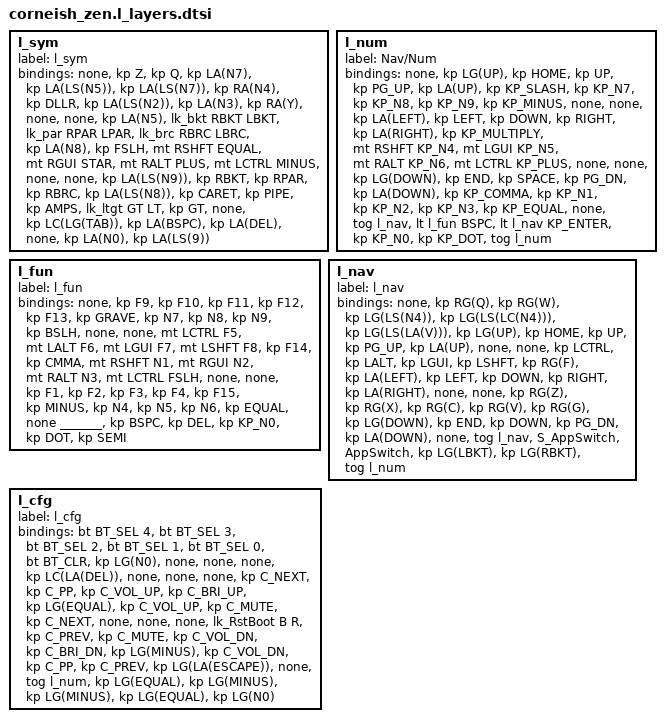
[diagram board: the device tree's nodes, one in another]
/*
 Building for a 36 key on a 42 key board (outside column is unused)
 */

//                                       Symbol & math (for Mac)
//  * left paired symbols are "linger keys" via hold taps. Tap for left, hold for pair with insertion point between
//╭────────────────────────────────────────────╮ ╭──────────────────────────────────────────╮
//|    Z   |    Q    |   ¶   |   †   |    ‡    | |   ¢   |    $   |    €   |    £   |   ¥   |
//|    §   |    [    |   (   |   {   |    •    | |   /   |    =   |    *   |    +   |   -   |
//|    ·   |    ]    |   )   |   }   |    °    | |   ^   |    |   |    &   |    <   |   >   |
//╰──────────────────╮       | dwdlt |  dwdr   | | &none |    ¡   |        ╭────────────────╯
//                   ╰─────────────────────────╯ ╰─────────────────────────╯
                l_sym {
                    label = "l_sym";
                    bindings = <
&none &kp Z &kp Q &kp LA(N7) &kp LA(LS(N5)) &kp LA(LS(N7))                         &kp RA(N4) &kp DLLR  &kp LA(LS(N2)) &kp LA(N3) &kp RA(Y)  &none
&none &kp LA(N5)  &lk_bkt RBKT LBKT &lk_par RPAR LPAR &lk_brc RBRC LBRC &kp LA(N8) &kp FSLH   &mt RSHFT EQUAL &mt RGUI STAR   &mt RALT PLUS  &mt LCTRL MINUS &none
&none &kp LA(LS(N9)) &kp RBKT &kp RPAR &kp RBRC &kp LA(LS(N8))                     &kp CARET  &kp PIPE  &kp AMPS     &lk_ltgt GT LT  &kp GT  &none
                &kp LC(LG(TAB)) &kp LA(BSPC)   &kp LA(DEL)              &none      &kp LA(N0) &kp LA(LS(9))
                    >;
                };

//                                        Nav & NumPad (standard)
//╭─────────────────────────────────────────────╮ ╭────────────────────────────────────────╮
//|   Top  |  HOME  |   UP   |  PG_UP |   ¶up   | |    /   |   7   |   8   |   9   |   -   |
//|  Lword |  LEFT  |  DOWN  |   RGT  |  Rword  | |    *   |  S/4  |  G/5  |  A/6  |  C/+  |
//|   Bot  |   END  |   SPC  |  PG_DN |   ¶dn   | |    ,   |   1   |   2   |   3   |   =   |
//╰─────────────────╮   tog  |  BSPC  |KP_ENTER | |    0   |   .   |  tog  ╭───────────────╯
//                  ╰───────────────────────────╯ ╰────────────────────────╯
                l_num {
                    label = "Nav/Num";
                    bindings = <

&none &kp LG(UP)    &kp HOME  &kp UP    &kp PG_UP  &kp LA(UP)    &kp KP_SLASH    &kp KP_N7 &kp KP_N8 &kp KP_N9 &kp KP_MINUS &none
&none &kp LA(LEFT)  &kp LEFT  &kp DOWN  &kp RIGHT  &kp LA(RIGHT) &kp KP_MULTIPLY &mt RSHFT KP_N4 &mt LGUI KP_N5 &mt RALT KP_N6 &mt LCTRL KP_PLUS   &none
&none &kp LG(DOWN)  &kp END   &kp SPACE &kp PG_DN  &kp LA(DOWN)  &kp KP_COMMA    &kp KP_N1 &kp KP_N2 &kp KP_N3 &kp KP_EQUAL &none
                &tog l_nav &lt l_fun BSPC &lt l_nav KP_ENTER     &kp KP_N0       &kp KP_DOT  &tog l_num
                        >;
                };

//                                         Fkey & Num Row (optimized)
//╭──────────────────────────────────────────────╮ ╭───────────────────────────────────────╮
//|    F9   |  F10   |  F11   |  F12   |   F13   | |   `   |   7   |   8   |   9   |   \   |
//|   C/F5  |  A/F6  |  G/F7  |  S/F8  |   F14   | |   ,   |  S/1  |  G/2  |  A/3  |  C//  |
//|    F1   |   F2   |   F3   |   F4   |   F15   | |   -   |   4   |   5   |   6   |   =   |
//╰──────────────────╮        |  dwdlt |  dwdrt  | |   0   |   .   |   ;   ╭───────────────╯
//                   ╰───────────────────────────╯ ╰───────────────────────╯

                l_fun {
                    label = "l_fun";
                    bindings = <

&none &kp F9       &kp F10     &kp F11     &kp F12      &kp F13  &kp GRAVE  &kp N7       &kp N8      &kp N9      &kp BSLH       &none
&none &mt LCTRL F5 &mt LALT F6 &mt LGUI F7 &mt LSHFT F8 &kp F14  &kp CMMA   &mt RSHFT N1 &mt RGUI N2 &mt RALT N3 &mt LCTRL FSLH &none
&none &kp F1       &kp F2      &kp F3      &kp F4       &kp F15  &kp MINUS  &kp N4       &kp N5      &kp N6      &kp EQUAL      &none
                               _______     &kp BSPC    &kp DEL   &kp KP_N0  &kp DOT      &kp SEMI
                        >;
                };


//                                     shorcuts & Navigation
//╭─────────────────────────────────────────────╮ ╭────────────────────────────────────────────╮
//|  close |   quit  | ScrCp | SelCp |  pstmtch | |   Top   |  HOME  |   UP   |  PG_UP | ¶up   |
//|  ctrl  |   alt   |  gui  |  shft |   Find   | |  Lword  |  LEFT  |  DOWN  |   RGT  | Rword |
//|  undo  |   cut   |  copy |  pste |  findAgn | |   Botm  |   END  |  DOWN  |  PG_DN | ¶dn   |
//╰──────────────────╮       | dwdlt |   dwdrt  | |   back  |  fwd   |  num   ╭────────────────╯
//                   ╰──────────────────────────╯ ╰───────────────────────────╯
                l_nav {
                    label = "l_nav";
                    bindings = <
&none &kp RG(Q) &kp RG(W) &kp LG(LS(N4)) &kp LG(LS(LC(N4))) &kp LG(LS(LA(V))) &kp LG(UP)   &kp HOME &kp UP     &kp PG_UP &kp LA(UP)    &none
&none &kp LCTRL &kp LALT  &kp LGUI       &kp LSHFT     &kp RG(F)              &kp LA(LEFT) &kp LEFT &kp DOWN   &kp RIGHT &kp LA(RIGHT) &none
&none &kp RG(Z) &kp RG(X) &kp RG(C)      &kp RG(V)     &kp RG(G)              &kp LG(DOWN) &kp END  &kp DOWN   &kp PG_DN &kp LA(DOWN)  &none
                            &tog l_nav  &S_AppSwitch &AppSwitch               &kp LG(LBKT)  &kp LG(RBKT) &tog l_num
                    >;
                };

//                                     Keyboard & System Settings
/*   L_CFG Keyboard Configuration (left) and Media Settings (right)
         ╭───────────────────────────────────────────────╮                            ╭────────────────────────────────────────────────╮
      __ │  BT3     BT2     BT1     BT0        BT_Clr    │                            │ SK_ZOOMRST KC_NUM  KC_EJCT KC_NO   (C(A(del))) │ RGB_MOD
 RGB_VAI │  HD_AKTg L_0     L_1     KC_VOLU    KC_BRIU   |                            | SK_ZOOMOUT KC_MPRV KC_MUTE KC_MNXT KC_NO       │ RGB_SAI
 RGB_HUI │  QK_BOOT AG_SWAP AG_NORM KC_VOLD    KC_BRID   │ RGB_VAD  __    __  RGB_SAD │ SK_ZOOMIN  KC_MRWD KC_MPLY KC_MFFD KILL        │ RGB_HUD
         ╰──────────────────╮   __  SK_ZOOMOUT SK_ZOOMIN │ __                     __  │ SK_ZOOMIN  SK_ZOOMOUT __   ╭───────────────────╯
                    __   __ ╰────────────────────────────╯                            ╰────────────────────────────╯   __     __
*/
                l_cfg {
                    label = "l_cfg";
                    bindings = <
&bt BT_SEL 4 &bt BT_SEL 3    &bt BT_SEL 2 &bt BT_SEL 1 &bt BT_SEL 0 &bt BT_CLR   &kp LG(N0)    &none        &none      &none      &kp LC(LA(DEL)) &none
&none        &none           &kp C_NEXT   &kp C_PP     &kp C_VOL_UP &kp C_BRI_UP &kp LG(EQUAL) &kp C_VOL_UP &kp C_MUTE &kp C_NEXT &none &none
&none        &lk_RstBoot B R &kp C_PREV   &kp C_MUTE   &kp C_VOL_DN &kp C_BRI_DN &kp LG(MINUS) &kp C_VOL_DN &kp C_PP   &kp C_PREV &kp LG(LA(ESCAPE)) &none
                                          &tog l_num &kp LG(EQUAL) &kp LG(MINUS) &kp LG(MINUS) &kp LG(EQUAL)  &kp LG(N0)
                        >;
                };
